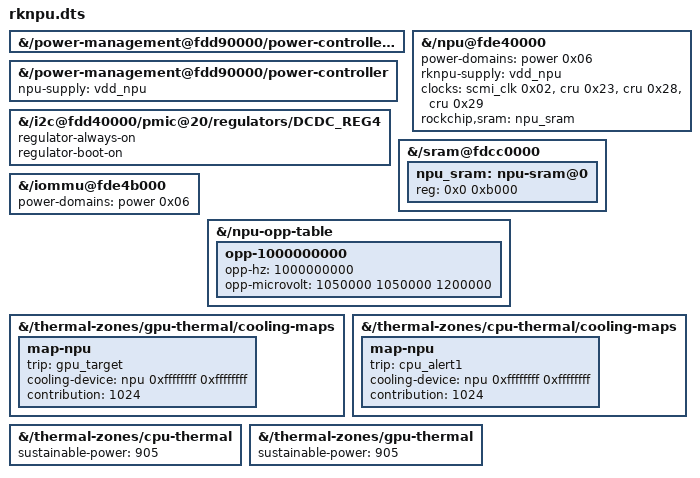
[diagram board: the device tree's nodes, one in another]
/dts-v1/;
/plugin/;

/ {
	/* Enable PD6 (NPU power domain) */
	fragment@0 {
		target-path = "/power-management@fdd90000/power-controller/power-domain@6";
		__overlay__ {
			status = "okay";
		};
	};

	/* Wire npu-supply to power controller */
	fragment@1 {
		target-path = "/power-management@fdd90000/power-controller";
		__overlay__ {
			npu-supply = <&vdd_npu>;
		};
	};

	/* Force vdd_npu regulator always-on */
	fragment@2 {
		target-path = "/i2c@fdd40000/pmic@20/regulators/DCDC_REG4";
		__overlay__ {
			regulator-always-on;
			regulator-boot-on;
		};
	};

	/* Add power-domains, supply, SCMI+CRU clocks, and SRAM to NPU node */
	fragment@3 {
		target-path = "/npu@fde40000";
		npu: __overlay__ {
			#cooling-cells = <2>;
			power-domains = <&power 0x06>;
			rknpu-supply = <&vdd_npu>;
			clocks = <&scmi_clk 0x02>,
				 <&cru 0x23>,
				 <&cru 0x28>,
				 <&cru 0x29>;
			clock-names = "scmi_clk", "clk", "aclk", "hclk";
			rockchip,sram = <&npu_sram>; /* SRAM_PHANDLE */
		};
	};

	/* SRAM_SPLIT_BEGIN — replaced by install.sh based on RKNPU_SRAM_PERCENT */
	fragment@6 {
		target-path = "/sram@fdcc0000";
		__overlay__ {
			#address-cells = <1>;
			#size-cells = <1>;

			npu_sram: npu-sram@0 {
				reg = <0x0 0xb000>;
			};
		};
	};
	/* SRAM_SPLIT_END */

	/* Add power-domains to IOMMU node */
	fragment@4 {
		target-path = "/iommu@fde4b000";
		__overlay__ {
			power-domains = <&power 0x06>;
		};
	};

	/* Add 1 GHz OPP entry (SCMI supports up to 1000 MHz stable) */
	fragment@7 {
		target-path = "/npu-opp-table";
		__overlay__ {
			opp-1000000000 {
				opp-hz = /bits/ 64 <1000000000>;
				opp-microvolt = <1050000 1050000 1200000>;
			};
		};
	};

	/* Bind NPU cooling to both thermal zones at 75°C trips.
	 * RK3568 has 2 TSADC channels: ch0=CPU, ch1=GPU. No NPU sensor.
	 * Binding to both ensures throttling regardless of which sensor heats first.
	 * contribution=1024 matches Rockchip 6.6 reference (equal weight). */
	fragment@8 {
		target-path = "/thermal-zones/gpu-thermal/cooling-maps";
		__overlay__ {
			map-npu {
				trip = <&gpu_target>;
				cooling-device = <&npu 0xffffffff 0xffffffff>;
				contribution = <1024>;
			};
		};
	};

	fragment@9 {
		target-path = "/thermal-zones/cpu-thermal/cooling-maps";
		__overlay__ {
			map-npu {
				trip = <&cpu_alert1>;
				cooling-device = <&npu 0xffffffff 0xffffffff>;
				contribution = <1024>;
			};
		};
	};

	/* Set sustainable-power on cpu-thermal for fair_share governor.
	 * 905 mW matches Rockchip 6.6 reference for RK3568. */
	fragment@10 {
		target-path = "/thermal-zones/cpu-thermal";
		__overlay__ {
			sustainable-power = <905>;
		};
	};

	fragment@11 {
		target-path = "/thermal-zones/gpu-thermal";
		__overlay__ {
			sustainable-power = <905>;
		};
	};
};
